# STM32H503 register map
File version: 0.3
CPU: CM33 r0p0, little endian, MPU, FPU, 4 interrupt priority bits
Registers are 32-bit, read-write, reset 0x0 unless marked. A register's access mark holds for its fields unless they carry their own. Offsets are from the block's base; [hi:lo] are bit positions.

## TIM6 — Basic timers
Base 0x40001000
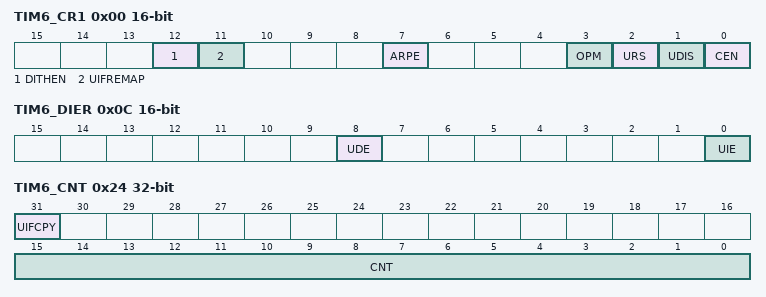
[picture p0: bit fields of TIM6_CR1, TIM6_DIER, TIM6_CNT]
0x00 TIM6_CR1 16-bit — TIM6 control register 1
  [12] DITHEN — Dithering enable Note: The DITHEN bit can only be modified when CEN bit is reset.
  [11] UIFREMAP — UIF status bit remapping
  [7] ARPE — Auto-reload preload enable
  [3] OPM — One-pulse mode
  [2] URS — Update request source This bit is set and cleared by software to select the UEV event sources. Counter overflow/underflow Setting the UG bit Update generation through the slave mode controller
  [1] UDIS — Update disable This bit is set and cleared by software to enable/disable UEV event generation. Counter overflow/underflow Setting the UG bit Update generation through the slave mode controller Buffered registers are then loaded with their preload values.
  [0] CEN — Counter enable CEN is cleared automatically in one-pulse mode, when an update event occurs.
0x04 TIM6_CR2 16-bit — TIM6 control register 2
  [6:4] MMS — Master mode selection These bits are used to select the information to be sent in master mode to slave timers for synchronization (TRGO). The combination is as follows: Note: The clock of the slave timer or he peripheral receiving the tim_trgo must be enabled prior to receive events from the master timer, and must not be changed on-the-fly while triggers are received from the master timer.
0x0C TIM6_DIER 16-bit — TIM6 DMA/Interrupt enable register
  [8] UDE — Update DMA request enable
  [0] UIE — Update interrupt enable
0x10 TIM6_SR 16-bit — TIM6 status register
  [0] UIF — Update interrupt flag This bit is set by hardware on an update event. It is cleared by software. On counter overflow if UDIS = 0 in the TIMx_CR1 register. When CNT is reinitialized by software using the UG bit in the TIMx_EGR register, if URS = 0 and UDIS = 0 in the TIMx_CR1 register.
0x14 TIM6_EGR 16-bit wo — TIM6 event generation register
  [0] UG — Update generation This bit can be set by software, it is automatically cleared by hardware.
0x24 TIM6_CNT access per field — TIM6 counter
  [31] UIFCPY ro — UIF copy This bit is a read-only copy of the UIF bit of the TIMx_ISR register. If the UIFREMAP bit in TIMx_CR1 is reset, bit 31 is reserved and read as 0.
  [15:0] CNT rw — Counter value Non-dithering mode (DITHEN = 0) The register holds the counter value. Dithering mode (DITHEN = 1) The register only holds the non-dithered part in CNT[15:0]. The fractional part is not available.
0x28 TIM6_PSC 16-bit — TIM6 prescaler
  [15:0] PSC — Prescaler value The counter clock frequency ftim_cnt_ck is equal to ftim_psc_ck / (PSC[15:0] + 1). PSC contains the value to be loaded into the active prescaler register at each update event. (including when the counter is cleared through UG bit of TIMx_EGR register.
0x2C TIM6_ARR reset 0xFFFF — TIM6 auto-reload register
  [19:0] ARR — Auto-reload value ARR is the value to be loaded into the actual auto-reload register. Refer to for more details about ARR update and behavior. The counter is blocked while the auto-reload value is null. Non-dithering mode (DITHEN = 0) The register holds the auto-reload value in ARR[15:0]. The ARR[19:16] bits are reserved. Dithering mode (DITHEN = 1) The register holds the integer part in ARR[19:4]. The ARR[3:0] bitfield contains the dithered part.

## TIM7 — Basic timers
Base 0x40001400
Registers as TIM6 (with TIM6 read as TIM7).

## WWDG — System window watchdog
Base 0x40002C00
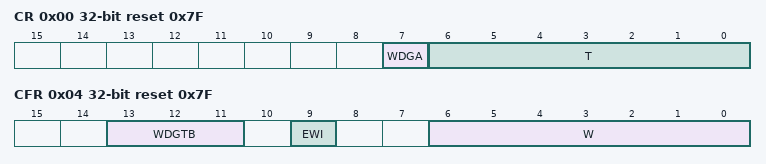
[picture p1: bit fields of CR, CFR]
0x00 CR reset 0x7F — WWDG control register
  [7] WDGA — Activation bit This bit is set by software and only cleared by hardware after a reset. When WDGA = 1, the watchdog can generate a reset.
  [6:0] T — 7-bit counter (MSB to LSB) These bits contain the value of the watchdog counter, decremented every (4096 x 2WDGTB[2:0]) PCLK cycles. A reset is produced when it is decremented from 0x40 to 0x3F (T6 becomes cleared).
0x04 CFR reset 0x7F — WWDG configuration register
  [13:11] WDGTB — Timer base The timebase of the prescaler can be modified as follows:
  [9] EWI — Early wakeup interrupt When set, an interrupt occurs whenever the counter reaches the value 0x40. This interrupt is only cleared by hardware after a reset.
  [6:0] W — 7-bit window value These bits contain the window value to be compared with the down-counter.
0x08 SR — WWDG status register
  [0] EWIF — Early wakeup interrupt flag This bit is set by hardware when the counter has reached the value 0x40. It must be cleared by software by writing ‘0’. Writing ‘1’ has no effect. This bit is also set if the interrupt is not enabled.
